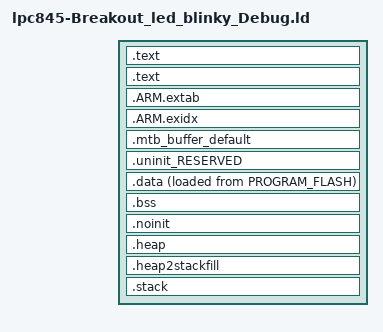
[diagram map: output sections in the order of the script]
/*
 * GENERATED FILE - DO NOT EDIT
 * Copyright (c) 2008 - 2013 Code Red Technologies Ltd, 
 * Copyright 2015, 2018 NXP
 * (c) NXP Semiconductors 2013-2018
 * Generated linker script file for LPC845
 * Created from linkscript.ldt by FMCreateLinkLibraries
 * Using Freemarker v2.3.23
 * MCUXpresso IDE v10.3.0 [Build 2200] [2018-12-03] on Dec 19, 2018 11:35:12 AM
 */

INCLUDE "lpc845-Breakout_led_blinky_Debug_library.ld"
INCLUDE "lpc845-Breakout_led_blinky_Debug_memory.ld"

ENTRY(ResetISR)

SECTIONS
{
    /* MAIN TEXT SECTION */
    .text : ALIGN(4)
    {
        FILL(0xff)
        __vectors_start__ = ABSOLUTE(.) ;
        KEEP(*(.isr_vector))
        /* Global Section Table */
        . = ALIGN(4) ;
        __section_table_start = .;
        __data_section_table = .;
        LONG(LOADADDR(.data));
        LONG(    ADDR(.data));
        LONG(  SIZEOF(.data));
        __data_section_table_end = .;
        __bss_section_table = .;
        LONG(    ADDR(.bss));
        LONG(  SIZEOF(.bss));
        __bss_section_table_end = .;
        __section_table_end = . ;
        /* End of Global Section Table */

        *(.after_vectors*)

        /* Code Read Protection data */
        . = 0x2FC ;
        PROVIDE(__CRP_WORD_START__ = .) ;
        KEEP(*(.crp))
        PROVIDE(__CRP_WORD_END__ = .) ;
        ASSERT(!(__CRP_WORD_START__ == __CRP_WORD_END__), "Linker CRP Enabled, but no CRP_WORD provided within application");
        /* End of Code Read Protection */
    } > PROGRAM_FLASH

    .text : ALIGN(4)
    {
       *(.text*)
       *(.rodata .rodata.* .constdata .constdata.*)
       . = ALIGN(4);
    } > PROGRAM_FLASH
    /*
     * for exception handling/unwind - some Newlib functions (in common
     * with C++ and STDC++) use this. 
     */
    .ARM.extab : ALIGN(4) 
    {
        *(.ARM.extab* .gnu.linkonce.armextab.*)
    } > PROGRAM_FLASH

    __exidx_start = .;

    .ARM.exidx : ALIGN(4)
    {
        *(.ARM.exidx* .gnu.linkonce.armexidx.*)
    } > PROGRAM_FLASH
    __exidx_end = .;
 
    _etext = .;
        
    /* MAIN DATA SECTION */
        /* Default MTB section */
        .mtb_buffer_default (NOLOAD) :
        {
           KEEP(*(.mtb*))
        } > SRAM
    .uninit_RESERVED : ALIGN(4)
    {
        KEEP(*(.bss.$RESERVED*))
        . = ALIGN(4) ;
        _end_uninit_RESERVED = .;
    } > SRAM

    /* Main DATA section (SRAM) */
    .data : ALIGN(4)
    {
       FILL(0xff)
       _data = . ;
       *(vtable)
       *(.ramfunc*)
       *(.data*)
       . = ALIGN(4) ;
       _edata = . ;
    } > SRAM AT>PROGRAM_FLASH

    /* MAIN BSS SECTION */
    .bss : ALIGN(4)
    {
        _bss = .;
        *(.bss*)
        *(COMMON)
        . = ALIGN(4) ;
        _ebss = .;
        PROVIDE(end = .);
    } > SRAM

    /* DEFAULT NOINIT SECTION */
    .noinit (NOLOAD): ALIGN(4)
    {
        _noinit = .;
        *(.noinit*) 
         . = ALIGN(4) ;
        _end_noinit = .;
    } > SRAM

    /* Reserve and place Heap within memory map */
    _HeapSize = 0x400;
    .heap :  ALIGN(4)
    {
        _pvHeapStart = .;
        . += _HeapSize;
        . = ALIGN(4);
        _pvHeapLimit = .;
    } > SRAM

     _StackSize = 0x400;
     /* Reserve space in memory for Stack */
    .heap2stackfill  :
    {
        . += _StackSize;
    } > SRAM
    /* Locate actual Stack in memory map */
    .stack ORIGIN(SRAM) + LENGTH(SRAM) - _StackSize - 0:  ALIGN(4)
    {
        _vStackBase = .;
        . = ALIGN(4);
        _vStackTop = . + _StackSize;
    } > SRAM

    /* ## Create checksum value (used in startup) ## */
    PROVIDE(__valid_user_code_checksum = 0 - 
                                         (_vStackTop 
                                         + (ResetISR + 1) 
                                         + (( DEFINED(NMI_Handler) ? NMI_Handler : M0_NMI_Handler ) + 1) 
                                         + (( DEFINED(HardFault_Handler) ? HardFault_Handler : M0_HardFault_Handler ) + 1) 
                                         )
           );

    /* Provide basic symbols giving location and size of main text
     * block, including initial values of RW data sections. Note that
     * these will need extending to give a complete picture with
     * complex images (e.g multiple Flash banks).
     */
    _image_start = LOADADDR(.text);
    _image_end = LOADADDR(.data) + SIZEOF(.data);
    _image_size = _image_end - _image_start;
}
